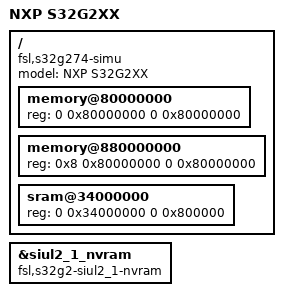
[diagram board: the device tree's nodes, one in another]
// SPDX-License-Identifier: GPL-2.0+
/*
 * Copyright 2021-2022 NXP
 *
 * This program is free software; you can redistribute it and/or modify
 * it under the terms of the GNU General Public License as published by
 * the Free Software Foundation; either version 2 of the License, or
 * (at your option) any later version.
 */

#include "fsl-s32g.dtsi"
/ {
	model = "NXP S32G2XX";
	compatible = "fsl,s32g274-simu", "fsl,s32g274", "fsl,s32gen1",
				 "arm,vexpress,v2p-aarch64", "arm,vexpress";

	memory@80000000 {
		device_type = "memory";
		reg = <0 0x80000000 0 0x80000000>;
	};

	memory@880000000 {
		device_type = "memory";
		reg = <0x8 0x80000000 0 0x80000000>;
	};

	sram@34000000 {
		device_type = "memory";
		reg = <0 0x34000000 0 0x800000>;
	};
};

&siul2_1_nvram {
	compatible = "fsl,s32g2-siul2_1-nvram";
};
